AUTOSAR XML (schema 00051)
package /Components
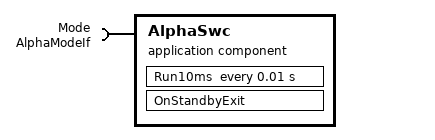
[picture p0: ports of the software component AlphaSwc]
  application sw component type AlphaSwc
    require port Mode: required-interface=AlphaModeIf
    behavior AlphaSwc_IB
      timing event Event_Run10ms: start-on-event=Run10ms, period=0.01
      swc mode switch event Event_OnStandbyExit: start-on-event=OnStandbyExit, activation=ON-EXIT, mode=Mode.Mode.Standby
      runnable Run10ms: symbol=AlphaSwc_Run10ms
      runnable OnStandbyExit: symbol=AlphaSwc_OnStandbyExit
package /Interfaces
  mode switch interface AlphaModeIf: is-service=true
    mode group Mode: type=AlphaModes
package /ModeDeclarationGroups
  mode declaration group AlphaModes: initial-mode=Startup
    6 x mode:
      Startup
      Run
      Standby
      Rundown
      Shutdown
      Sleep
